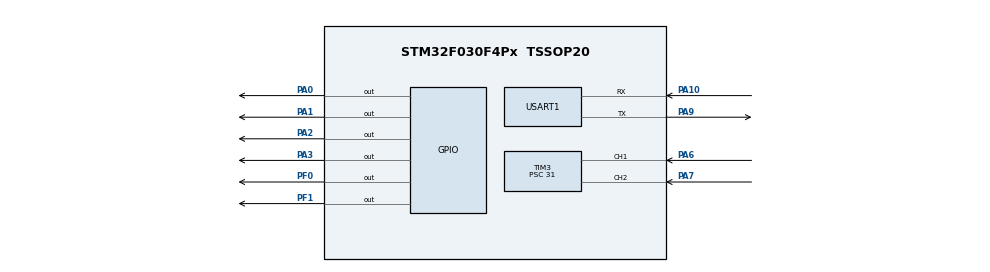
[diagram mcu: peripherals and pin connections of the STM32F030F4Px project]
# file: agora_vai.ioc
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Mcu.Family=STM32F0
Mcu.Name=STM32F030F4Px
Mcu.Package=TSSOP20
NVIC.TIM14_IRQn=true\:0\:0\:false\:false\:true\:true\:true
NVIC.TIM3_IRQn=true\:0\:0\:false\:false\:true\:true\:true
PA0.Signal=GPIO_Output
PA1.Signal=GPIO_Output
PA10.Mode=Asynchronous
PA10.Signal=USART1_RX
PA2.Signal=GPIO_Output
PA3.Signal=GPIO_Output
PA6.Signal=S_TIM3_CH1
PA7.Signal=S_TIM3_CH2
PA9.Mode=Asynchronous
PA9.Signal=USART1_TX
PF0-OSC_IN.Signal=GPIO_Output
PF1-OSC_OUT.Signal=GPIO_Output
ProjectManager.HeapSize=0x200
ProjectManager.StackSize=0x400
ProjectManager.TargetToolchain=TrueSTUDIO
SH.S_TIM3_CH1.0=TIM3_CH1,Input_Capture1_from_TI1
SH.S_TIM3_CH2.0=TIM3_CH2,Input_Capture2_from_TI2
TIM3.Channel-Input_Capture1_from_TI1=TIM_CHANNEL_1
TIM3.Channel-Input_Capture2_from_TI2=TIM_CHANNEL_2
TIM3.ICFilter_CH1=15
TIM3.ICFilter_CH2=15
TIM3.ICPolarity_CH1=TIM_INPUTCHANNELPOLARITY_FALLING
TIM3.ICPolarity_CH2=TIM_INPUTCHANNELPOLARITY_FALLING
TIM3.Period=60000
TIM3.Prescaler=31
USART1.VirtualMode-Asynchronous=VM_ASYNC
VP_TIM14_VS_ClockSourceINT.Mode=Enable_Timer
VP_TIM3_VS_ClockSourceINT.Mode=Internal
board=custom

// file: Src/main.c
/* USER CODE BEGIN Header */
/**
  ******************************************************************************
  * @file           : main.c
  * @brief          : Main program body
  ******************************************************************************
  * @attention
  *
  * <h2><center>&copy; Copyright (c) 2019 STMicroelectronics.
  * All rights reserved.</center></h2>
  *
  * This software component is licensed by ST under BSD 3-Clause license,
  * the "License"; You may not use this file except in compliance with the
  * License. You may obtain a copy of the License at:
  *                        opensource.org/licenses/BSD-3-Clause
  *
  ******************************************************************************
  */
/* USER CODE END Header */

#include "main.h"
#include "stm32f0xx_hal.h"
#include "stm32f0xx.h"
#include <string.h>

/* USER CODE BEGIN Includes */

#define INIT_CHAR "&"
#define END_CHAR "\n"

/* USER CODE END Includes */

TIM_HandleTypeDef htim3;
TIM_HandleTypeDef htim14;

UART_HandleTypeDef huart1;
DMA_HandleTypeDef hdma_usart1_rx;
DMA_HandleTypeDef hdma_usart1_tx;

/* USER CODE BEGIN PV */

// variaveis do projeto
// verifica os ldrs
int ldr1 = 0;
int ldr2 = 0;

// contagem do tempo
int count_time = 0;
int count_time_seg = 0;

int conta_carro1 = 0;
int conta_carro2 = 0;
char sconta_carro1[5];
char sconta_carro2[5];
int contou = 0;

// semaforo que tá fechado
int sem_fechado = 1;
// semaforo a ser fechado
int fecha_sem = 2;

/* USER CODE END PV */

void SystemClock_Config(void);
static void MX_GPIO_Init(void);
static void MX_TIM3_Init(void);
static void MX_USART1_UART_Init(void);
static void MX_DMA_Init(void);
static void MX_TIM14_Init(void);

void fecha_semaforo(int semaforo);

void sendData(uint8_t *message, int size);

int main(void)
{

  /* MCU Configuration--------------------------------------------------------*/

  /* Reset of all peripherals, Initializes the Flash interface and the Systick. */
  HAL_Init();

  /* Configure the system clock */
  SystemClock_Config();

  /* Initialize all configured peripherals */
  MX_GPIO_Init();
  MX_TIM3_Init();
  MX_USART1_UART_Init();
  MX_DMA_Init();
  MX_TIM14_Init();
  /* USER CODE BEGIN 2 */
  // iniciando os canais
  HAL_TIM_IC_Start_IT(&htim3, TIM_CHANNEL_1); // ldr 1
  HAL_TIM_IC_Start_IT(&htim3, TIM_CHANNEL_2); // ldr 2
  // iniciando o timer base
  HAL_TIM_Base_Start_IT(&htim14);
  // Iniciando o DMA

  HAL_GPIO_WritePin(GPIOF, GPIO_PIN_0, GPIO_PIN_SET); // liga o led vermelho do s1
  HAL_GPIO_WritePin(GPIOF, GPIO_PIN_1, GPIO_PIN_RESET); // desliga o led amarelo do s1
  HAL_GPIO_WritePin(GPIOA, GPIO_PIN_0, GPIO_PIN_RESET); // desliga o led verde do s1
  HAL_GPIO_WritePin(GPIOA, GPIO_PIN_1, GPIO_PIN_RESET); // desliga o led vermelho do s2
  HAL_GPIO_WritePin(GPIOA, GPIO_PIN_2, GPIO_PIN_RESET); // desliga o led amarelo do s2
  HAL_GPIO_WritePin(GPIOA, GPIO_PIN_3, GPIO_PIN_SET); // liga o led verde do s2

  /* USER CODE END 2 */

  /* Infinite loop */
  // inicia o s1 fechado e o s2 aberto

  while (1)
  {
	  //faz a troca dos semaforos

	  /* USER CODE BEGIN 3 */
	  if(sem_fechado != fecha_sem){
	  			  fecha_semaforo(fecha_sem);
	  			  count_time = 0;
	  		  }

	  		  HAL_Delay(4000);

	  		  itoa(conta_carro1, sconta_carro1, 10);
	  		  itoa(conta_carro2, sconta_carro2, 10);
	  		  char msg1[100] = "Número de atualizações do sinal 1:";
	  		  char msg2[100] = "Número de atualizações do sinal 2:";
	  		  strcat(msg1, sconta_carro1);
	  		  strcat(msg2, sconta_carro2);
	  		  strcat(msg1, "\n");
	  		  strcat(msg2, "\n");

	  		   HAL_UART_Transmit(&huart1, (uint8_t*)msg1, strlen(msg1), HAL_MAX_DELAY);
	  		   HAL_UART_Transmit(&huart1, (uint8_t*)msg2, strlen(msg2), HAL_MAX_DELAY);

	  		  contou = 0;
  }
  /* USER CODE END 3 */
}

void SystemClock_Config(void)
{
  RCC_OscInitTypeDef RCC_OscInitStruct = {0};
  RCC_ClkInitTypeDef RCC_ClkInitStruct = {0};
  RCC_PeriphCLKInitTypeDef PeriphClkInit = {0};

  /** Initializes the CPU, AHB and APB busses clocks
  */
  RCC_OscInitStruct.OscillatorType = RCC_OSCILLATORTYPE_HSI;
  RCC_OscInitStruct.HSIState = RCC_HSI_ON;
  RCC_OscInitStruct.HSICalibrationValue = RCC_HSICALIBRATION_DEFAULT;
  RCC_OscInitStruct.PLL.PLLState = RCC_PLL_NONE;
  if (HAL_RCC_OscConfig(&RCC_OscInitStruct) != HAL_OK)
  {
    Error_Handler();
  }
  /** Initializes the CPU, AHB and APB busses clocks
  */
  RCC_ClkInitStruct.ClockType = RCC_CLOCKTYPE_HCLK|RCC_CLOCKTYPE_SYSCLK
                              |RCC_CLOCKTYPE_PCLK1;
  RCC_ClkInitStruct.SYSCLKSource = RCC_SYSCLKSOURCE_HSI;
  RCC_ClkInitStruct.AHBCLKDivider = RCC_SYSCLK_DIV1;
  RCC_ClkInitStruct.APB1CLKDivider = RCC_HCLK_DIV1;

  if (HAL_RCC_ClockConfig(&RCC_ClkInitStruct, FLASH_LATENCY_0) != HAL_OK)
  {
    Error_Handler();
  }
  PeriphClkInit.PeriphClockSelection = RCC_PERIPHCLK_USART1;
  PeriphClkInit.Usart1ClockSelection = RCC_USART1CLKSOURCE_PCLK1;
  if (HAL_RCCEx_PeriphCLKConfig(&PeriphClkInit) != HAL_OK)
  {
    Error_Handler();
  }
}

static void MX_TIM3_Init(void)
{

  TIM_ClockConfigTypeDef sClockSourceConfig = {0};
  TIM_MasterConfigTypeDef sMasterConfig = {0};
  TIM_IC_InitTypeDef sConfigIC = {0};

  htim3.Instance = TIM3;
  htim3.Init.Prescaler = 31;
  htim3.Init.CounterMode = TIM_COUNTERMODE_UP;
  htim3.Init.Period = 60000;
  htim3.Init.ClockDivision = TIM_CLOCKDIVISION_DIV1;
  htim3.Init.AutoReloadPreload = TIM_AUTORELOAD_PRELOAD_DISABLE;
  if (HAL_TIM_Base_Init(&htim3) != HAL_OK)
  {
    Error_Handler();
  }
  sClockSourceConfig.ClockSource = TIM_CLOCKSOURCE_INTERNAL;
  if (HAL_TIM_ConfigClockSource(&htim3, &sClockSourceConfig) != HAL_OK)
  {
    Error_Handler();
  }
  if (HAL_TIM_IC_Init(&htim3) != HAL_OK)
  {
    Error_Handler();
  }
  sMasterConfig.MasterOutputTrigger = TIM_TRGO_RESET;
  sMasterConfig.MasterSlaveMode = TIM_MASTERSLAVEMODE_DISABLE;
  if (HAL_TIMEx_MasterConfigSynchronization(&htim3, &sMasterConfig) != HAL_OK)
  {
    Error_Handler();
  }
  sConfigIC.ICPolarity = TIM_INPUTCHANNELPOLARITY_FALLING;
  sConfigIC.ICSelection = TIM_ICSELECTION_DIRECTTI;
  sConfigIC.ICPrescaler = TIM_ICPSC_DIV1;
  sConfigIC.ICFilter = 15;
  if (HAL_TIM_IC_ConfigChannel(&htim3, &sConfigIC, TIM_CHANNEL_1) != HAL_OK)
  {
    Error_Handler();
  }
  if (HAL_TIM_IC_ConfigChannel(&htim3, &sConfigIC, TIM_CHANNEL_2) != HAL_OK)
  {
    Error_Handler();
  }

}

static void MX_TIM14_Init(void)
{

  htim14.Instance = TIM14;
  htim14.Init.Prescaler = 31999;
  htim14.Init.CounterMode = TIM_COUNTERMODE_UP;
  htim14.Init.Period = 99;
  htim14.Init.ClockDivision = TIM_CLOCKDIVISION_DIV1;
  htim14.Init.AutoReloadPreload = TIM_AUTORELOAD_PRELOAD_DISABLE;
  if (HAL_TIM_Base_Init(&htim14) != HAL_OK)
  {
    Error_Handler();
  }

}

static void MX_USART1_UART_Init(void)
{

  huart1.Instance = USART1;
  huart1.Init.BaudRate = 9600;
  huart1.Init.WordLength = UART_WORDLENGTH_8B;
  huart1.Init.StopBits = UART_STOPBITS_1;
  huart1.Init.Parity = UART_PARITY_NONE;
  huart1.Init.Mode = UART_MODE_TX_RX;
  huart1.Init.HwFlowCtl = UART_HWCONTROL_NONE;
  huart1.Init.OverSampling = UART_OVERSAMPLING_16;
  huart1.Init.OneBitSampling = UART_ONE_BIT_SAMPLE_DISABLE;
  huart1.AdvancedInit.AdvFeatureInit = UART_ADVFEATURE_NO_INIT;
  if (HAL_UART_Init(&huart1) != HAL_OK)
  {
    Error_Handler();
  }

}

static void MX_DMA_Init(void)
{

  /* DMA controller clock enable */
  __HAL_RCC_DMA1_CLK_ENABLE();

  /* DMA interrupt init */
  /* DMA1_Channel2_3_IRQn interrupt configuration */
  HAL_NVIC_SetPriority(DMA1_Channel2_3_IRQn, 0, 0);
  HAL_NVIC_EnableIRQ(DMA1_Channel2_3_IRQn);

}

static void MX_GPIO_Init(void)
{
  GPIO_InitTypeDef GPIO_InitStruct = {0};

  /* GPIO Ports Clock Enable */
  __HAL_RCC_GPIOF_CLK_ENABLE();
  __HAL_RCC_GPIOA_CLK_ENABLE();

  /*Configure GPIO pin Output Level */
  HAL_GPIO_WritePin(GPIOF, GPIO_PIN_0|GPIO_PIN_1, GPIO_PIN_RESET);

  /*Configure GPIO pin Output Level */
  HAL_GPIO_WritePin(GPIOA, GPIO_PIN_0|GPIO_PIN_1|GPIO_PIN_2|GPIO_PIN_3, GPIO_PIN_RESET);

  /*Configure GPIO pins : PF0 PF1 */
  GPIO_InitStruct.Pin = GPIO_PIN_0|GPIO_PIN_1;
  GPIO_InitStruct.Mode = GPIO_MODE_OUTPUT_PP;
  GPIO_InitStruct.Pull = GPIO_NOPULL;
  GPIO_InitStruct.Speed = GPIO_SPEED_FREQ_LOW;
  HAL_GPIO_Init(GPIOF, &GPIO_InitStruct);

  /*Configure GPIO pins : PA0 PA1 PA2 PA3 */
  GPIO_InitStruct.Pin = GPIO_PIN_0|GPIO_PIN_1|GPIO_PIN_2|GPIO_PIN_3;
  GPIO_InitStruct.Mode = GPIO_MODE_OUTPUT_PP;
  GPIO_InitStruct.Pull = GPIO_NOPULL;
  GPIO_InitStruct.Speed = GPIO_SPEED_FREQ_LOW;
  HAL_GPIO_Init(GPIOA, &GPIO_InitStruct);

  /*Configure GPIO pins : PA5 */
    GPIO_InitStruct.Pin = GPIO_PIN_5;
    GPIO_InitStruct.Mode = GPIO_MODE_OUTPUT_PP;
    GPIO_InitStruct.Pull = GPIO_NOPULL;
    GPIO_InitStruct.Speed = GPIO_SPEED_FREQ_LOW;
    HAL_GPIO_Init(GPIOA, &GPIO_InitStruct);

}

/* USER CODE BEGIN 4 */
void HAL_TIM_IC_CaptureCallback(TIM_HandleTypeDef *htim){
	if (htim->Instance==TIM3){
		//sinal do ldr 1
		if(htim->Channel==TIM_CHANNEL_1){

		}
		//sinal do ldr 2
		if(htim->Channel==TIM_CHANNEL_2){

		}
	}
}

void HAL_TIM_PeriodElapsedCallback(TIM_HandleTypeDef *htim){
	if (htim->Instance==TIM14){
		ldr1 = HAL_GPIO_ReadPin(GPIOA, GPIO_PIN_7); // porta 13
		ldr2 = HAL_GPIO_ReadPin(GPIOA, GPIO_PIN_6); // porta 12

		// verifica se o carro está parado no s1 fechado e sem carro no s2
		if(ldr2 == 1 && sem_fechado == 1 && ldr1 == 0){
			// fechando o s2
			HAL_GPIO_WritePin(GPIOA,GPIO_PIN_2,GPIO_PIN_SET); // liga amarelo S2
			HAL_GPIO_WritePin(GPIOA,GPIO_PIN_3,GPIO_PIN_RESET); // desliga verde S2
			// HAL_Delay(500);
			HAL_GPIO_WritePin(GPIOA, GPIO_PIN_1, GPIO_PIN_SET); // liga vermelho S2
			HAL_GPIO_WritePin(GPIOA, GPIO_PIN_2, GPIO_PIN_RESET); // desliga amarelo S2
			// HAL_Delay(500);
			// abrindo o s1
			HAL_GPIO_WritePin(GPIOF, GPIO_PIN_0, GPIO_PIN_RESET); // deslida vermelho S1
			HAL_GPIO_WritePin(GPIOA, GPIO_PIN_0, GPIO_PIN_SET); // liga verde S1
			sem_fechado = 2;
			fecha_sem = 1;
			if (contou == 0) {
				conta_carro1 = conta_carro1 + 1;
				contou = 1;
			}

		} else if (ldr2 == 1 && sem_fechado == 1 && ldr1 == 1) {
			if (contou == 0) {
				conta_carro1 = conta_carro1 + 1;
				conta_carro2 = conta_carro2 + 1;
				contou = 1;
			}
		} else if (ldr2 == 1 && sem_fechado == 2 && ldr1 == 0) {
			if (contou == 0) {
				conta_carro1 = conta_carro1 + 1;
				contou = 1;
			}
		} else if (ldr2 == 1 && sem_fechado == 2 && ldr1 == 1) {
			if (contou == 0) {
				conta_carro1 = conta_carro1 + 1;
				conta_carro2 = conta_carro2 + 1;
				contou = 1;
			}
		} else if (ldr2 == 0 && sem_fechado == 1 && ldr1 == 0) {

		} else if (ldr2 == 0 && sem_fechado == 2 && ldr1 == 0) {

		} else if (ldr2 == 0 && sem_fechado == 1 && ldr1 == 1) {
			if (contou == 0) {
				conta_carro2 = conta_carro2 + 1;
				contou = 1;
			}
		} else if (ldr2 == 0 && sem_fechado == 2 && ldr1 == 1) {
			// fechando o s1
			HAL_GPIO_WritePin(GPIOF,GPIO_PIN_1,GPIO_PIN_SET); // liga amarelo S1
			HAL_GPIO_WritePin(GPIOA,GPIO_PIN_0,GPIO_PIN_RESET); // desliga verde S1
			//HAL_Delay(500);
			HAL_GPIO_WritePin(GPIOF,GPIO_PIN_0,GPIO_PIN_SET); // liga vermelho S1
			HAL_GPIO_WritePin(GPIOF,GPIO_PIN_1,GPIO_PIN_RESET); // desliga amarelo S1
			// abrindo o s2
			HAL_GPIO_WritePin(GPIOA,GPIO_PIN_1,GPIO_PIN_RESET); // desliga vermelho S2
			HAL_GPIO_WritePin(GPIOA,GPIO_PIN_3,GPIO_PIN_SET); // liga verde S2
			sem_fechado = 1;
			fecha_sem = 2;
			if (contou == 0) {
				conta_carro2 = conta_carro2 + 1;
				contou = 1;
			}
		}

	}
}

void fecha_semaforo(int semaforo) {
	if(semaforo == 1) {
	//5 segundos de transição do verde para vermelho
		HAL_GPIO_WritePin(GPIOF,GPIO_PIN_1,GPIO_PIN_SET); // liga amarelo S1
		HAL_GPIO_WritePin(GPIOA,GPIO_PIN_0,GPIO_PIN_RESET); // desliga verde S1
		HAL_Delay(3000);
		// Fecha semaforo 1
		HAL_GPIO_WritePin(GPIOF,GPIO_PIN_0,GPIO_PIN_SET); // liga vermelho S1
		HAL_GPIO_WritePin(GPIOF,GPIO_PIN_1,GPIO_PIN_RESET); // desliga amarelo S1
		// Delay com ambos os semaforos em vermelho
		HAL_Delay(3000);
		// Abre o semaforo 2
		HAL_GPIO_WritePin(GPIOA,GPIO_PIN_1,GPIO_PIN_RESET); // desliga vermelho S2
		HAL_GPIO_WritePin(GPIOA,GPIO_PIN_3,GPIO_PIN_SET); // liga verde S2
		sem_fechado = 1;
		fecha_sem = 2;
	} else if(semaforo == 2) {
		//5 segundos de transição do verde para vermelho
		HAL_GPIO_WritePin(GPIOA,GPIO_PIN_2,GPIO_PIN_SET); // liga amarelo S2
		HAL_GPIO_WritePin(GPIOA,GPIO_PIN_3,GPIO_PIN_RESET); // desliga verde S2
		HAL_Delay(3000);
		// Fecha o semaforo 2
		HAL_GPIO_WritePin(GPIOA, GPIO_PIN_1, GPIO_PIN_SET); // liga vermelho S2
		HAL_GPIO_WritePin(GPIOA, GPIO_PIN_2, GPIO_PIN_RESET); // desliga amarelo S2
		// Delay com ambos os semaforos em vermelho
		HAL_Delay(3000);
		// Abre o semaforo 1
		HAL_GPIO_WritePin(GPIOF, GPIO_PIN_0, GPIO_PIN_RESET); // deslida vermelho S1
		HAL_GPIO_WritePin(GPIOA, GPIO_PIN_0, GPIO_PIN_SET); // liga verde S1
		sem_fechado = 2;
		fecha_sem = 1;
	}
}

uint32_t getUs(void) {
	uint32_t usTicks = HAL_RCC_GetSysClockFreq() / 1000000;
	register uint32_t ms, cycle_cnt;
	do {
		ms = HAL_GetTick();
		cycle_cnt = SysTick->VAL;
	} while (ms != HAL_GetTick());

	return (ms * 1000) + (usTicks * 1000 - cycle_cnt) / usTicks;
}

void Delay_Us(uint32_t micros) {
	uint32_t start = getUs();
	while (getUs()-start < (uint32_t) micros);
}

/* USER CODE END 4 */

void Error_Handler(void)
{
}

/************************ (C) COPYRIGHT STMicroelectronics *****END OF FILE****/
